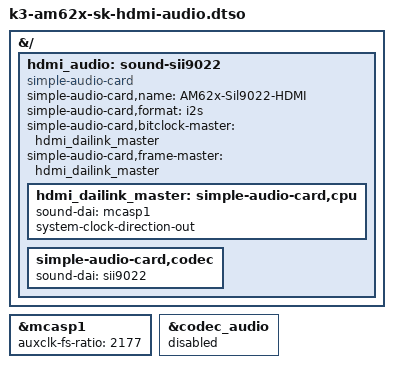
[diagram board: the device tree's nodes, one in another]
// SPDX-License-Identifier: GPL-2.0
/**
 * Audio playback via HDMI for AM625-SK and AM62-LP SK.
 *
 * Links:
 * AM625 SK: https://www.ti.com/tool/SK-AM62
 * AM62-LP SK: https://www.ti.com/tool/SK-AM62-LP
 *
 * Copyright (C) 2023 Texas Instruments Incorporated - http://www.ti.com/
 */

/dts-v1/;
/plugin/;

&{/} {
	hdmi_audio: sound-sii9022 {
		compatible = "simple-audio-card";
		simple-audio-card,name = "AM62x-Sil9022-HDMI";
		simple-audio-card,format = "i2s";
		simple-audio-card,bitclock-master = <&hdmi_dailink_master>;
		simple-audio-card,frame-master = <&hdmi_dailink_master>;

		hdmi_dailink_master: simple-audio-card,cpu {
			sound-dai = <&mcasp1>;
			system-clock-direction-out;
		};

		simple-audio-card,codec {
			sound-dai = <&sii9022>;
		};
	};
};

&mcasp1 {
	auxclk-fs-ratio = <2177>;
};

&codec_audio {
	status = "disabled";
};
